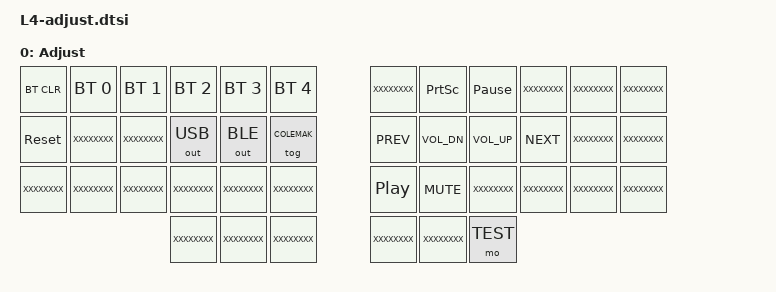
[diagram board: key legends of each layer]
/**
 *
 */

/ {
  keymap {
    compatible = "zmk,keymap";

	adjust_layer {
		label = "Adjust";
		bindings = <
// ╭───────────────┬───────────────┬───────────────┬───────────────┬───────────────┬───────────────╮   ╭───────────────┬───────────────┬───────────────┬───────────────┬───────────────┬───────────────╮
	&bt BT_CLR      &bt BT_SEL 0    &bt BT_SEL 1    &bt BT_SEL 2    &bt BT_SEL 3    &bt BT_SEL 4     	XXXXXXXX   		&kp PSCRN       &kp PAUSE_BREAK XXXXXXXX        XXXXXXXX        XXXXXXXX
// ├───────────────├───────────────┼───────────────┼───────────────┼───────────────┼───────────────┤   ├───────────────├───────────────┼───────────────┼───────────────┼───────────────┼───────────────┤
	&sys_reset     	XXXXXXXX		XXXXXXXX        &out OUT_USB   	&out OUT_BLE    &tog COLEMAK        &kp C_PREV      &kp C_VOL_DN    &kp C_VOL_UP    &kp C_NEXT      XXXXXXXX        XXXXXXXX
// ├───────────────├───────────────┼───────────────┼───────────────┼───────────────┼───────────────┤   ├───────────────├───────────────┼───────────────┼───────────────┼───────────────┼───────────────┤
	XXXXXXXX      	XXXXXXXX		XXXXXXXX        XXXXXXXX		XXXXXXXX        XXXXXXXX            &kp C_PP        &kp C_MUTE     	XXXXXXXX        XXXXXXXX        XXXXXXXX        XXXXXXXX
// ╰───────────────┴───────────────┴───────────────┼───────────────┼───────────────┼───────────────┤   ├───────────────├───────────────┼───────────────┼───────────────┴───────────────┴───────────────╯
                                    	            XXXXXXXX       	XXXXXXXX        XXXXXXXX           	XXXXXXXX        XXXXXXXX        &mo TEST
//                                                 ╰───────────────┴───────────────┴───────────────╯   ╰───────────────┴───────────────┴───────────────╯
			>;
		};
	};
};
